# ATSAM4LC8C register map
Vendor: Atmel Corporation; Series: SAM4L; File version: A
CPU: CM4 r0p1, little endian, MPU, no FPU, 4 interrupt priority bits
Registers are 32-bit, write-only, reset 0x0 unless marked. A register's access mark holds for its fields unless they carry their own. Offsets are from the block's base; [hi:lo] are bit positions.

## PICOUART
Base 0x400F1400; register names take the prefix PICOUART_
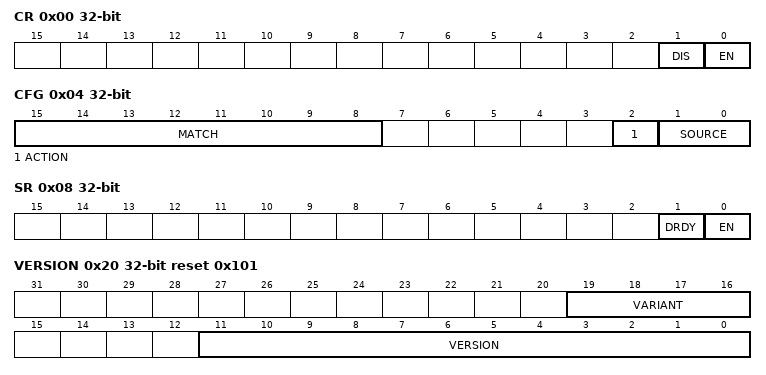
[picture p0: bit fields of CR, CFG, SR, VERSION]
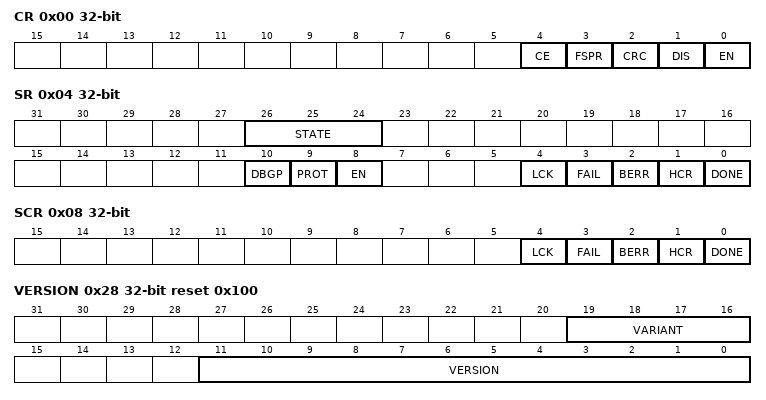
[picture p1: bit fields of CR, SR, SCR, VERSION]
0x00 CR — Control Register
  [1] DIS — Disable
  [0] EN — Enable
0x04 CFG rw — Configuration Register
  [15:8] MATCH — Data Match
  [2] ACTION — Action to perform
  [1:0] SOURCE — Source Enable Mode
0x08 SR ro — Status Register
  [1] DRDY — Data Ready Interrupt Status
  [0] EN — Enable Interrupt Status
0x0C RHR ro — Receive Holding Register
  [31:0] CDATA — Received Data
0x20 VERSION ro reset 0x101
  [19:16] VARIANT — Variant Number
  [11:0] VERSION — Version Number

## SMAP — System Manager Access Port
Base 0x400A3000; register names take the prefix SMAP_
0x00 CR — Control Register
  [4] CE — Chip Erase
  [3] FSPR — Flash Supplementary Page Read
  [2] CRC — User Page Read
  [1] DIS — Disable
  [0] EN — Enable
0x04 SR ro — Status Register
  [26:24] STATE
  [10] DBGP — Debugger Present
  [9] PROT — Protected
  [8] EN — Enabled
  [4] LCK — Lock
  [3] FAIL — Failure
  [2] BERR — Bus error
  [1] HCR — Hold Core reset
  [0] DONE — Operation done
0x08 SCR — Status Clear Register
  [4] LCK — Lock error
  [3] FAIL — Failure
  [2] BERR — Bus error
  [1] HCR — Hold Core Register
  [0] DONE
0x0C ADDR rw — Address Register
  [31:2] ADDR — Address Value
0x10 LENGTH rw
  [31:2] LENGTH
0x14 DATA rw
  [31:0] DATA — Generic data register
0x28 VERSION ro reset 0x100
  [19:16] VARIANT — Variant number
  [11:0] VERSION — Version number
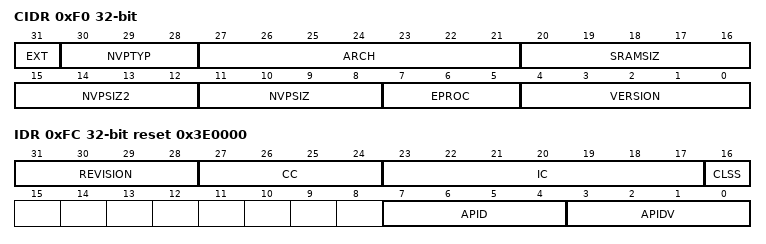
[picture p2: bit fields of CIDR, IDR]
0xF0 CIDR ro — Chip ID Register
  [31] EXT — Extension Flag
  [30:28] NVPTYP — Nonvolatile Program Memory Type
  [27:21] ARCH — Architecture Identifier
  [20:16] SRAMSIZ — Internal SRAM Size
  [15:12] NVPSIZ2 — Second Nonvolatile Program Memory Size
  [11:8] NVPSIZ — Nonvolatile Program Memory Size
  [7:5] EPROC — Embedded Processor
  [4:0] VERSION — Version of the Device
0xF4 EXID ro — Chip ID Extension Register
  [31:0] EXID — Chip ID Extension
0xFC IDR ro reset 0x3E0000 — AP Identification register
  [31:28] REVISION
  [27:24] CC — JEP-106 Continuation Code
  [23:17] IC — JEP-106 Identity Code
  [16] CLSS — Class
  [7:4] APID — AP Identification
  [3:0] APIDV — AP Identification Variant

## TRNG — True Random Number Generator
Base 0x40068000; register names take the prefix TRNG_
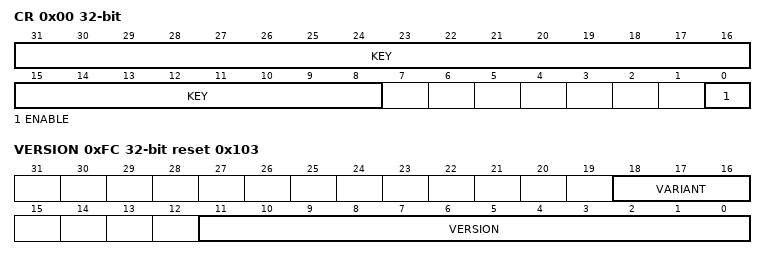
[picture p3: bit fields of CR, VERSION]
0x00 CR — Control Register
  [31:8] KEY — Security Key
  [0] ENABLE — Enables the TRNG to provide random values
0x10 IER — Interrupt Enable Register
  [0] DATRDY — Data Ready Interrupt Enable
0x14 IDR — Interrupt Disable Register
  [0] DATRDY — Data Ready Interrupt Disable
0x18 IMR ro — Interrupt Mask Register
  [0] DATRDY — Data Ready Interrupt Mask
0x1C ISR ro — Interrupt Status Register
  [0] DATRDY — Data Ready Interrupt Status
0x50 ODATA ro — Output Data Register
  [0] ODATA — Output Data
0xFC VERSION ro reset 0x103
  [18:16] VARIANT — Variant Number
  [11:0] VERSION — Version Number

## WDT — Watchdog Timer
Base 0x400F0C00; register names take the prefix WDT_
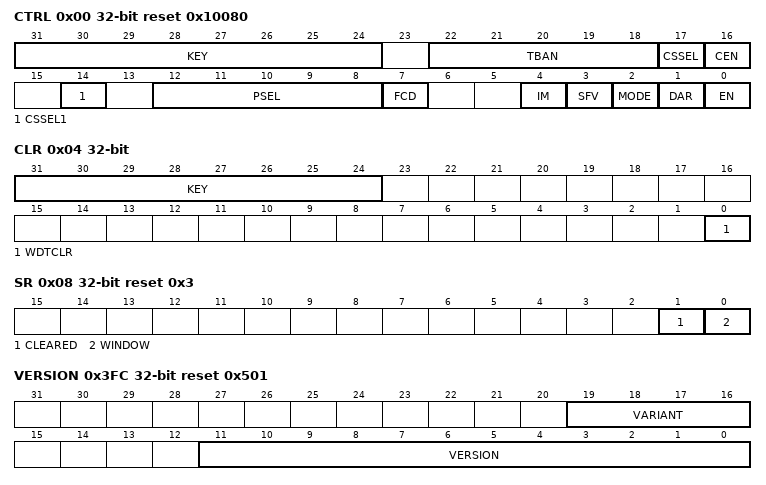
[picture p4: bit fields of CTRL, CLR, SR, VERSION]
0x00 CTRL rw reset 0x10080 — Control Register
  [31:24] KEY
  [22:18] TBAN — TBAN Prescale Select
  [17] CSSEL — Clock Source Selection0
  [16] CEN — Clock Enable
  [14] CSSEL1 — Clock Source Selection1
  [12:8] PSEL — Timeout Prescale Select
  [7] FCD — WDT Fuse Calibration Done
  [4] IM — WDT Interruput Mode
  [3] SFV — WDT Store Final Value
  [2] MODE — WDT Mode
  [1] DAR — WDT Disable After Reset
  [0] EN — WDT Enable
    0=WDT is disabled; 1=WDT is enabled
0x04 CLR — Clear Register
  [31:24] KEY
  [0] WDTCLR — Clear WDT counter
0x08 SR ro reset 0x3 — Status Register
  [1] CLEARED — WDT cleared
  [0] WINDOW — WDT in window
0x0C IER — Interrupt Enable Register
  [2] WINT — Watchdog Interrupt
0x10 IDR — Interrupt Disable Register
  [2] WINT — Watchdog Interrupt
0x14 IMR ro — Interrupt Mask Register
  [2] WINT — Watchdog Interrupt
0x18 ISR ro — Interrupt Status Register
  [2] WINT — Watchdog Interrupt
0x1C ICR — Interrupt Clear Register
  [2] WINT — Watchdog Interrupt
0x3FC VERSION ro reset 0x501
  [19:16] VARIANT — Variant number
  [11:0] VERSION — Version number
